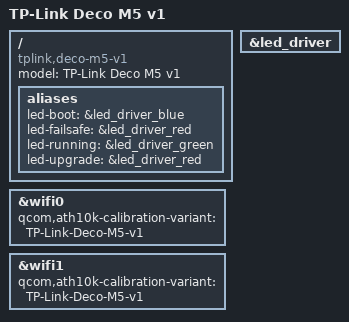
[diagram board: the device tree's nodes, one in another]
// SPDX-License-Identifier: ISC
// Copyright (c) 2015, The Linux Foundation. All rights reserved.
// Copyright (c) 2021, Frank Veltmans <veltmans.frank@gmail.com>

#include "qcom-ipq4019-deco-m5.dtsi"

/ {
	model = "TP-Link Deco M5 v1";
	compatible = "tplink,deco-m5-v1", "qcom,ipq4019";

	aliases {
		led-boot = &led_driver_blue;
		led-failsafe = &led_driver_red;
		led-running = &led_driver_green;
		led-upgrade = &led_driver_red;
	};
};

&led_driver {
	status = "okay";
};

&wifi0 {
	qcom,ath10k-calibration-variant = "TP-Link-Deco-M5-v1";
};

&wifi1 {
	qcom,ath10k-calibration-variant = "TP-Link-Deco-M5-v1";
};
